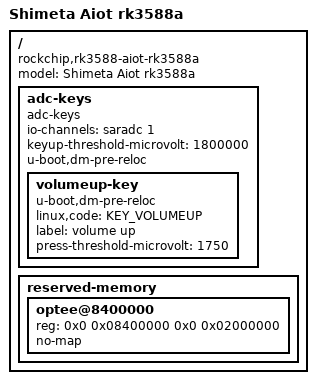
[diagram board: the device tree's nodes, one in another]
// SPDX-License-Identifier: (GPL-2.0+ OR MIT)
/*
 * Copyright (c) 2021 Rockchip Electronics Co., Ltd
 *
 */

/dts-v1/;
#include "rk3588.dtsi"
#include "rk3588-u-boot.dtsi"
#include <dt-bindings/input/input.h>

/ {
	model = "Shimeta Aiot rk3588a";
	compatible = "rockchip,rk3588-aiot-rk3588a", "rockchip,rk3588";

	adc-keys {
		compatible = "adc-keys";
		io-channels = <&saradc 1>;
		io-channel-names = "buttons";
		keyup-threshold-microvolt = <1800000>;
		u-boot,dm-pre-reloc;
		status = "okay";

		volumeup-key {
			u-boot,dm-pre-reloc;
			linux,code = <KEY_VOLUMEUP>;
			label = "volume up";
			press-threshold-microvolt = <1750>;
		};
	};

	reserved-memory {
                #address-cells = <2>;
                #size-cells = <2>;
                ranges;

                /* 必须添加：保护 OP-TEE v1.20 的内存不被 U-Boot 或 Kernel 覆盖 */
                optee@8400000 {
                    reg = <0x0 0x08400000 0x0 0x02000000>;
                    no-map;
                };
        };
};
